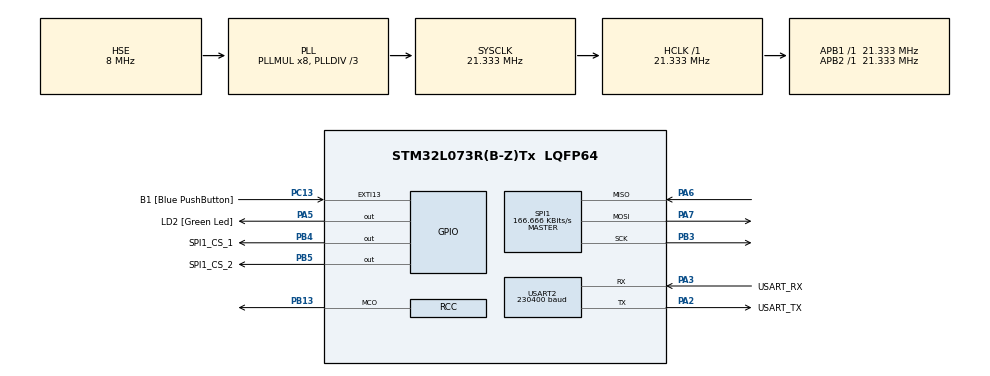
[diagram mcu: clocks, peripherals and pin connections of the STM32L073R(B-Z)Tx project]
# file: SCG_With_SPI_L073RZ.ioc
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Dma.Request0=USART2_TX
Dma.USART2_TX.0.Direction=DMA_MEMORY_TO_PERIPH
Dma.USART2_TX.0.Instance=DMA1_Channel4
Dma.USART2_TX.0.MemDataAlignment=DMA_MDATAALIGN_BYTE
Dma.USART2_TX.0.MemInc=DMA_MINC_ENABLE
Dma.USART2_TX.0.Mode=DMA_NORMAL
Dma.USART2_TX.0.PeriphDataAlignment=DMA_PDATAALIGN_BYTE
Dma.USART2_TX.0.PeriphInc=DMA_PINC_DISABLE
Dma.USART2_TX.0.Priority=DMA_PRIORITY_MEDIUM
Mcu.Family=STM32L0
Mcu.Name=STM32L073R(B-Z)Tx
Mcu.Package=LQFP64
NVIC.DMA1_Channel4_5_6_7_IRQn=true\:0\:0\:false\:false\:true\:false\:true\:true
NVIC.USART2_IRQn=true\:0\:0\:false\:false\:true\:true\:true\:true
PA13.GPIO_Label=TMS
PA13.Mode=Serial_Wire
PA13.Signal=SYS_SWDIO
PA14.GPIO_Label=TCK
PA14.Mode=Serial_Wire
PA14.Signal=SYS_SWCLK
PA2.GPIO_Label=USART_TX
PA2.Mode=Asynchronous
PA2.Signal=USART2_TX
PA3.GPIO_Label=USART_RX
PA3.Mode=Asynchronous
PA3.Signal=USART2_RX
PA5.GPIO_Label=LD2 [Green Led]
PA5.Signal=GPIO_Output
PA6.GPIO_Speed=GPIO_SPEED_FREQ_VERY_HIGH
PA6.Mode=Full_Duplex_Master
PA6.Signal=SPI1_MISO
PA7.GPIO_Speed=GPIO_SPEED_FREQ_VERY_HIGH
PA7.Mode=Full_Duplex_Master
PA7.Signal=SPI1_MOSI
PB13.Mode=Clock-out
PB13.Signal=RCC_MCO
PB3.GPIO_Speed=GPIO_SPEED_FREQ_VERY_HIGH
PB3.Mode=Full_Duplex_Master
PB3.Signal=SPI1_SCK
PB4.GPIO_Label=SPI1_CS_1
PB4.GPIO_Speed=GPIO_SPEED_FREQ_VERY_HIGH
PB4.Signal=GPIO_Output
PB5.GPIO_Label=SPI1_CS_2
PB5.GPIO_Speed=GPIO_SPEED_FREQ_VERY_HIGH
PB5.Signal=GPIO_Output
PC13.GPIO_Label=B1 [Blue PushButton]
PC13.GPIO_ModeDefaultEXTI=GPIO_MODE_IT_FALLING
PC13.Signal=GPXTI13
PC14-OSC32_IN.Mode=LSE-External-Oscillator
PC14-OSC32_IN.Signal=RCC_OSC32_IN
PC15-OSC32_OUT.Mode=LSE-External-Oscillator
PC15-OSC32_OUT.Signal=RCC_OSC32_OUT
PH0-OSC_IN.GPIO_Label=MCO
PH0-OSC_IN.Mode=HSE-External-Clock-Source
PH0-OSC_IN.Signal=RCC_OSC_IN
ProjectManager.HeapSize=0x200
ProjectManager.StackSize=0x400
ProjectManager.TargetToolchain=STM32CubeIDE
RCC.ADCFreq_Value=16000000
RCC.AHBFreq_Value=21333333.333333332
RCC.APB1Freq_Value=21333333.333333332
RCC.APB1TimFreq_Value=21333333.333333332
RCC.APB2Freq_Value=21333333.333333332
RCC.APB2TimFreq_Value=21333333.333333332
RCC.HCLKFreq_Value=21333333.333333332
RCC.HSE_VALUE=8000000
RCC.HSI16_VALUE=16000000
RCC.HSI48_VALUE=48000000
RCC.HSI_VALUE=16000000
RCC.MSI_VALUE=2097000
RCC.PLLDIV=RCC_PLLDIV_3
RCC.PLLMUL=RCC_PLLMUL_8
RCC.PLLSourceVirtual=RCC_PLLSOURCE_HSE
RCC.RCC_MCOSource=RCC_MCO1SOURCE_LSE
RCC.SYSCLKFreq_VALUE=21333333.333333332
RCC.SYSCLKSource=RCC_SYSCLKSOURCE_PLLCLK
RCC.VCOOutputFreq_Value=64000000
SPI1.BaudRatePrescaler=SPI_BAUDRATEPRESCALER_128
SPI1.CLKPhase=SPI_PHASE_1EDGE
SPI1.CLKPolarity=SPI_POLARITY_LOW
SPI1.CalculateBaudRate=166.666 KBits/s
SPI1.Direction=SPI_DIRECTION_2LINES
SPI1.Mode=SPI_MODE_MASTER
SPI1.VirtualType=VM_MASTER
USART2.BaudRate=230400
USART2.OverSampling=UART_OVERSAMPLING_16
USART2.VirtualMode-Asynchronous=VM_ASYNC
board=NUCLEO-L073RZ

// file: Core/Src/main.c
/* USER CODE BEGIN Header */
/**
  ******************************************************************************
  * @file           : main.c
  * @brief          : Main program body
  ******************************************************************************
  * @attention
  *
  * Copyright (c) 2025 STMicroelectronics.
  * All rights reserved.
  *
  * This software is licensed under terms that can be found in the LICENSE file
  * in the root directory of this software component.
  * If no LICENSE file comes with this software, it is provided AS-IS.
  *
  ******************************************************************************
  */
/* USER CODE END Header */
#include "main.h"

/* USER CODE BEGIN Includes */
#include "icm_42688_p_spi.h"
#include "sensor_array.h"
#include "uart.h"
/* USER CODE END Includes */

SPI_HandleTypeDef hspi1;

UART_HandleTypeDef huart2;
DMA_HandleTypeDef hdma_usart2_tx;

void SystemClock_Config(void);
static void MX_GPIO_Init(void);
static void MX_DMA_Init(void);
static void MX_USART2_UART_Init(void);
static void MX_SPI1_Init(void);

int main(void)
{

  /* MCU Configuration--------------------------------------------------------*/

  /* Reset of all peripherals, Initializes the Flash interface and the Systick. */
  HAL_Init();

  /* Configure the system clock */
  SystemClock_Config();

  /* Initialize all configured peripherals */
  MX_GPIO_Init();
  MX_DMA_Init();
  MX_USART2_UART_Init();
  MX_SPI1_Init();
  /* USER CODE BEGIN 2 */
  SetCSStartup();
  /* USER CODE END 2 */

  /* Infinite loop */
  /* USER CODE BEGIN WHILE */
  /************************* Code explaination ************************/
  //Sensors and Uart gets setup
  //The FIFO is used
  //In each loop of the main loop, a single packet of every sensor is read and modified to a reduced packet as given in the icm file
  //The sensor number is set to 99 if the FIFO is full when reading a measurement
  //This is put in an array of where one modified packet of each sensor is located after each other
  //This is feed to the uart part where an empty array for a table that is sent via uart is created
  //Every modified packet is changed to it value in a float and this is put digitwise into their respective row of the table
  //The table is sent in a long uart message via DMA
  /***************************************************************/

  static uint8_t dataBuffer[NUM_SENSORS * FIFO_PACKET_SIZE_MODIFIED] = {0};
  uint8_t error[] = "Error";

//  uint8_t tx_slew[2] = {0x13, 0x00};
//  uint8_t tx_data = 0x75 | 0x80;
//  uint8_t who_am_i = 0;

  uartSetup(&huart2);											//Prints Header and separator bar
  volatile HAL_StatusTypeDef status = SetupSensors(&hspi1);		//Initializes Sensors according to setup at the top of the icm file
  while(status == HAL_ERROR){									//Checks if setup worked
	  HAL_UART_Transmit(&huart2, error, sizeof(error), 1000);
  }
  FlushFIFOs(&hspi1);

  while (1)
  {
//	  HAL_GPIO_WritePin(GPIOB, GPIO_PIN_4, GPIO_PIN_RESET); /* Pin selection can be done in main.c */
//	  HAL_SPI_Transmit(&hspi1, tx_slew, 2, 1000);
//	  HAL_SPI_Transmit(&hspi1, &tx_data, 1, 1000);
//	  HAL_SPI_Receive(&hspi1, &who_am_i, 1, 1000);
//	  HAL_GPIO_WritePin(GPIOB, GPIO_PIN_4, GPIO_PIN_SET);
//	  HAL_Delay(100);

	  ReadSensors(&hspi1, dataBuffer);							//Reads sensor directly
	  uartSendMeasurement(&huart2, dataBuffer);					//Prints one measurement of all sensors
    /* USER CODE END WHILE */

  }
}

void SystemClock_Config(void)
{
  RCC_OscInitTypeDef RCC_OscInitStruct = {0};
  RCC_ClkInitTypeDef RCC_ClkInitStruct = {0};
  RCC_PeriphCLKInitTypeDef PeriphClkInit = {0};

  /** Configure the main internal regulator output voltage
  */
  __HAL_PWR_VOLTAGESCALING_CONFIG(PWR_REGULATOR_VOLTAGE_SCALE1);

  /** Configure LSE Drive Capability
  */
  HAL_PWR_EnableBkUpAccess();
  __HAL_RCC_LSEDRIVE_CONFIG(RCC_LSEDRIVE_LOW);

  /** Initializes the RCC Oscillators according to the specified parameters
  * in the RCC_OscInitTypeDef structure.
  */
  RCC_OscInitStruct.OscillatorType = RCC_OSCILLATORTYPE_HSE|RCC_OSCILLATORTYPE_LSE;
  RCC_OscInitStruct.HSEState = RCC_HSE_BYPASS;
  RCC_OscInitStruct.LSEState = RCC_LSE_ON;
  RCC_OscInitStruct.PLL.PLLState = RCC_PLL_ON;
  RCC_OscInitStruct.PLL.PLLSource = RCC_PLLSOURCE_HSE;
  RCC_OscInitStruct.PLL.PLLMUL = RCC_PLLMUL_8;
  RCC_OscInitStruct.PLL.PLLDIV = RCC_PLLDIV_3;
  if (HAL_RCC_OscConfig(&RCC_OscInitStruct) != HAL_OK)
  {
    Error_Handler();
  }

  /** Initializes the CPU, AHB and APB buses clocks
  */
  RCC_ClkInitStruct.ClockType = RCC_CLOCKTYPE_HCLK|RCC_CLOCKTYPE_SYSCLK
                              |RCC_CLOCKTYPE_PCLK1|RCC_CLOCKTYPE_PCLK2;
  RCC_ClkInitStruct.SYSCLKSource = RCC_SYSCLKSOURCE_PLLCLK;
  RCC_ClkInitStruct.AHBCLKDivider = RCC_SYSCLK_DIV1;
  RCC_ClkInitStruct.APB1CLKDivider = RCC_HCLK_DIV1;
  RCC_ClkInitStruct.APB2CLKDivider = RCC_HCLK_DIV1;

  if (HAL_RCC_ClockConfig(&RCC_ClkInitStruct, FLASH_LATENCY_1) != HAL_OK)
  {
    Error_Handler();
  }
  PeriphClkInit.PeriphClockSelection = RCC_PERIPHCLK_USART2;
  PeriphClkInit.Usart2ClockSelection = RCC_USART2CLKSOURCE_PCLK1;
  if (HAL_RCCEx_PeriphCLKConfig(&PeriphClkInit) != HAL_OK)
  {
    Error_Handler();
  }
  HAL_RCC_MCOConfig(RCC_MCO1, RCC_MCO1SOURCE_LSE, RCC_MCODIV_1);
}

static void MX_SPI1_Init(void)
{

  /* SPI1 parameter configuration*/
  hspi1.Instance = SPI1;
  hspi1.Init.Mode = SPI_MODE_MASTER;
  hspi1.Init.Direction = SPI_DIRECTION_2LINES;
  hspi1.Init.DataSize = SPI_DATASIZE_8BIT;
  hspi1.Init.CLKPolarity = SPI_POLARITY_LOW;
  hspi1.Init.CLKPhase = SPI_PHASE_1EDGE;
  hspi1.Init.NSS = SPI_NSS_SOFT;
  hspi1.Init.BaudRatePrescaler = SPI_BAUDRATEPRESCALER_128;
  hspi1.Init.FirstBit = SPI_FIRSTBIT_MSB;
  hspi1.Init.TIMode = SPI_TIMODE_DISABLE;
  hspi1.Init.CRCCalculation = SPI_CRCCALCULATION_DISABLE;
  hspi1.Init.CRCPolynomial = 7;
  if (HAL_SPI_Init(&hspi1) != HAL_OK)
  {
    Error_Handler();
  }

}

static void MX_USART2_UART_Init(void)
{

  huart2.Instance = USART2;
  huart2.Init.BaudRate = 230400;
  huart2.Init.WordLength = UART_WORDLENGTH_8B;
  huart2.Init.StopBits = UART_STOPBITS_1;
  huart2.Init.Parity = UART_PARITY_NONE;
  huart2.Init.Mode = UART_MODE_TX_RX;
  huart2.Init.HwFlowCtl = UART_HWCONTROL_NONE;
  huart2.Init.OverSampling = UART_OVERSAMPLING_16;
  huart2.Init.OneBitSampling = UART_ONE_BIT_SAMPLE_DISABLE;
  huart2.AdvancedInit.AdvFeatureInit = UART_ADVFEATURE_NO_INIT;
  if (HAL_UART_Init(&huart2) != HAL_OK)
  {
    Error_Handler();
  }

}

static void MX_DMA_Init(void)
{

  /* DMA controller clock enable */
  __HAL_RCC_DMA1_CLK_ENABLE();

  /* DMA interrupt init */
  /* DMA1_Channel4_5_6_7_IRQn interrupt configuration */
  HAL_NVIC_SetPriority(DMA1_Channel4_5_6_7_IRQn, 0, 0);
  HAL_NVIC_EnableIRQ(DMA1_Channel4_5_6_7_IRQn);

}

static void MX_GPIO_Init(void)
{
  GPIO_InitTypeDef GPIO_InitStruct = {0};

  /* GPIO Ports Clock Enable */
  __HAL_RCC_GPIOC_CLK_ENABLE();
  __HAL_RCC_GPIOH_CLK_ENABLE();
  __HAL_RCC_GPIOA_CLK_ENABLE();
  __HAL_RCC_GPIOB_CLK_ENABLE();

  /*Configure GPIO pin Output Level */
  HAL_GPIO_WritePin(LD2_GPIO_Port, LD2_Pin, GPIO_PIN_RESET);

  /*Configure GPIO pin Output Level */
  HAL_GPIO_WritePin(GPIOB, SPI1_CS_1_Pin|SPI1_CS_2_Pin, GPIO_PIN_RESET);

  /*Configure GPIO pin : B1_Pin */
  GPIO_InitStruct.Pin = B1_Pin;
  GPIO_InitStruct.Mode = GPIO_MODE_IT_FALLING;
  GPIO_InitStruct.Pull = GPIO_NOPULL;
  HAL_GPIO_Init(B1_GPIO_Port, &GPIO_InitStruct);

  /*Configure GPIO pin : LD2_Pin */
  GPIO_InitStruct.Pin = LD2_Pin;
  GPIO_InitStruct.Mode = GPIO_MODE_OUTPUT_PP;
  GPIO_InitStruct.Pull = GPIO_NOPULL;
  GPIO_InitStruct.Speed = GPIO_SPEED_FREQ_LOW;
  HAL_GPIO_Init(LD2_GPIO_Port, &GPIO_InitStruct);

  /*Configure GPIO pin : PB13 */
  GPIO_InitStruct.Pin = GPIO_PIN_13;
  GPIO_InitStruct.Mode = GPIO_MODE_AF_PP;
  GPIO_InitStruct.Pull = GPIO_NOPULL;
  GPIO_InitStruct.Speed = GPIO_SPEED_FREQ_LOW;
  GPIO_InitStruct.Alternate = GPIO_AF2_MCO;
  HAL_GPIO_Init(GPIOB, &GPIO_InitStruct);

  /*Configure GPIO pins : SPI1_CS_1_Pin SPI1_CS_2_Pin */
  GPIO_InitStruct.Pin = SPI1_CS_1_Pin|SPI1_CS_2_Pin;
  GPIO_InitStruct.Mode = GPIO_MODE_OUTPUT_PP;
  GPIO_InitStruct.Pull = GPIO_NOPULL;
  GPIO_InitStruct.Speed = GPIO_SPEED_FREQ_VERY_HIGH;
  HAL_GPIO_Init(GPIOB, &GPIO_InitStruct);

}

void Error_Handler(void)
{
  __disable_irq();
  while (1)
  {
  }
}
